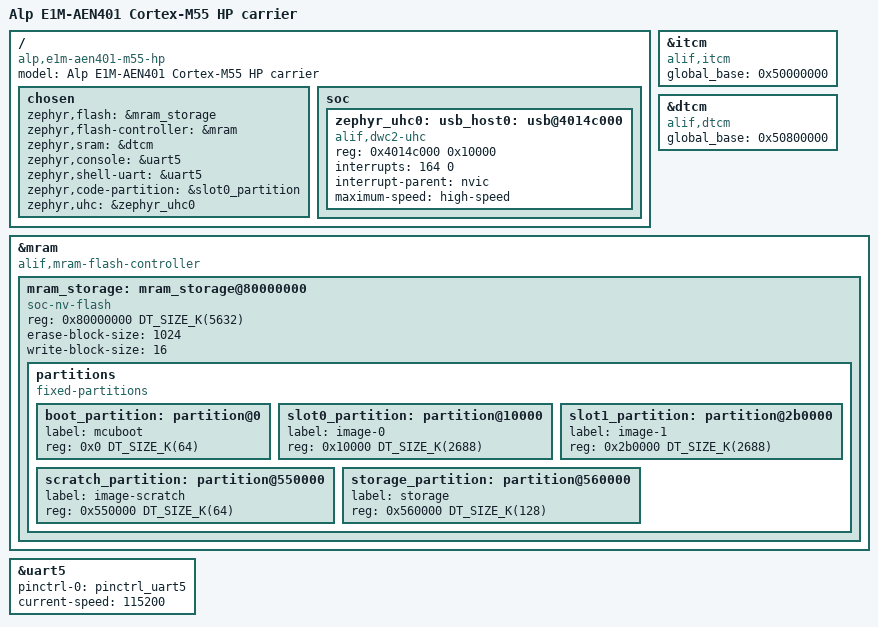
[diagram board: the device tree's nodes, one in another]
/*
 * Copyright (c) 2026 Alp Lab AB
 * SPDX-License-Identifier: Apache-2.0
 *
 * E1M-AEN401 (Alif Ensemble E4, AE402FA0E5597LE0) Cortex-M55-HP carrier,
 * for the Alp E1M-EVK.
 *
 * Mirrors the AEN801 M55-HP board structure (same E1M connector, same E1M-EVK
 * carrier) but targets the E4 SoC variant:
 *   - 2x Cortex-M55 + 2x Ethos-U55 + 1x Ethos-U85 (no A32 / Linux core)
 *   - 5632 KiB MRAM + up to 9984 KiB SRAM
 *   - Same Ensemble DWC2 USB2 IP as E8 (grounded against E3/E8 sibling)
 *
 * Console is retargeted to the E1M carrier UART0 (Alif UART5, P3_4/P3_5),
 * matching the AEN801 pin assignment for the E1M-EVK console.
 *
 * USB host: a Synopsys DWC2 OTG controller node (`alif,dwc2-uhc`) is
 * declared here so CONFIG_UHC_DWC2_ALIF and the usbh stack can be
 * activated at build time.  The reg base address and interrupt number are
 * placeholder values from the Ensemble E8 address map; they MUST be
 * confirmed against the E4 HWRM before any hardware bring-up attempt.
 * See TODO(aen401-bench) comments.
 *
 * MRAM partition map (5632 KiB, same layout as AEN801):
 *   mcuboot  0x000000  64 KiB
 *   image-0  0x010000  2688 KiB   (primary slot, code-partition)
 *   image-1  0x2b0000  2688 KiB   (secondary OTA slot)
 *   scratch  0x550000  64 KiB
 *   storage  0x560000  128 KiB
 */

/dts-v1/;

#include <alif/ensemble/ae402fa0e5597le0.dtsi>
#include <alif/ensemble/common/ensemble_rtss_hp.dtsi>
#include "alp_e1m_aen401_m55_hp-pinctrl.dtsi"

/ {
	model = "Alp E1M-AEN401 Cortex-M55 HP carrier";
	compatible = "alp,e1m-aen401-m55-hp";

	chosen {
		zephyr,flash = &mram_storage;
		zephyr,flash-controller = &mram;
		zephyr,sram = &dtcm;
		zephyr,console = &uart5;
		zephyr,shell-uart = &uart5;
		zephyr,code-partition = &slot0_partition;
		/*
		 * USB host controller -- bound by USBH_CONTROLLER_DEFINE in the
		 * alp_usb_host backend.  The label zephyr_uhc0 follows the Zephyr
		 * upstream host-sample convention (see samples/subsys/usb/host_uvc).
		 */
		zephyr,uhc = &zephyr_uhc0;
	};
};

/* ------------------------------------------------------------------ */
/* TCM global_base -- CPU-local -> system-bus address translation     */
/* ------------------------------------------------------------------ */

&itcm {
	compatible = "alif,itcm";
	/* RTSS-HP global TCM alias (same as AEN801 / E8). TODO(aen401-bench): confirm vs E4 TRM. */
	global_base = <0x50000000>;
};

&dtcm {
	compatible = "alif,dtcm";
	/* RTSS-HP global TCM alias. TODO(aen401-bench): confirm vs E4 TRM. */
	global_base = <0x50800000>;
};

/* ------------------------------------------------------------------ */
/* On-die MRAM as alif,mram-flash-controller (mirrors AEN801)         */
/* ------------------------------------------------------------------ */

&mram {
	compatible = "alif,mram-flash-controller";
	#address-cells = <1>;
	#size-cells = <1>;
	/delete-property/ zephyr,memory-region;
	/delete-property/ ranges;

	mram_storage: mram_storage@80000000 {
		compatible = "soc-nv-flash";
		reg = <0x80000000 DT_SIZE_K(5632)>;
		erase-block-size = <1024>;
		write-block-size = <16>;

		partitions {
			compatible = "fixed-partitions";
			#address-cells = <1>;
			#size-cells = <1>;

			boot_partition: partition@0 {
				label = "mcuboot";
				reg = <0x0 DT_SIZE_K(64)>;
			};

			slot0_partition: partition@10000 {
				label = "image-0";
				reg = <0x10000 DT_SIZE_K(2688)>;
			};

			slot1_partition: partition@2b0000 {
				label = "image-1";
				reg = <0x2b0000 DT_SIZE_K(2688)>;
			};

			scratch_partition: partition@550000 {
				label = "image-scratch";
				reg = <0x550000 DT_SIZE_K(64)>;
			};

			storage_partition: partition@560000 {
				label = "storage";
				reg = <0x560000 DT_SIZE_K(128)>;
			};
		};
	};
};

/* ------------------------------------------------------------------ */
/* Console: E1M carrier UART0 = Alif UART5 (P3_4 RX / P3_5 TX)       */
/* ------------------------------------------------------------------ */

&uart5 {
	status = "okay";
	pinctrl-0 = <&pinctrl_uart5>;
	pinctrl-names = "default";
	current-speed = <115200>;
};

/* ------------------------------------------------------------------ */
/* USB host: Synopsys DWC2 OTG in host (UHC) mode                     */
/* ------------------------------------------------------------------ */

/*
 * TODO(aen401-bench): the reg base 0x4014C000 and IRQ 164 are heuristic
 * placeholders derived from the Alif Ensemble address map family pattern.
 * Confirm both from the E4 HWRM (Confidential-Alif_E4_HWRM_v0.3.pdf)
 * before any hardware bring-up attempt.  The `alif,dwc2-uhc` compatible
 * binds the uhc_dwc2_alif skeleton driver (bench-gated, not yet functional).
 */
/ {
	soc {
		zephyr_uhc0: usb_host0: usb@4014c000 {
			compatible = "alif,dwc2-uhc";
			reg = <0x4014c000 0x10000>;
			interrupts = <164 0>;
			interrupt-parent = <&nvic>;
			maximum-speed = "high-speed";
			status = "okay";
		};
	};
};
